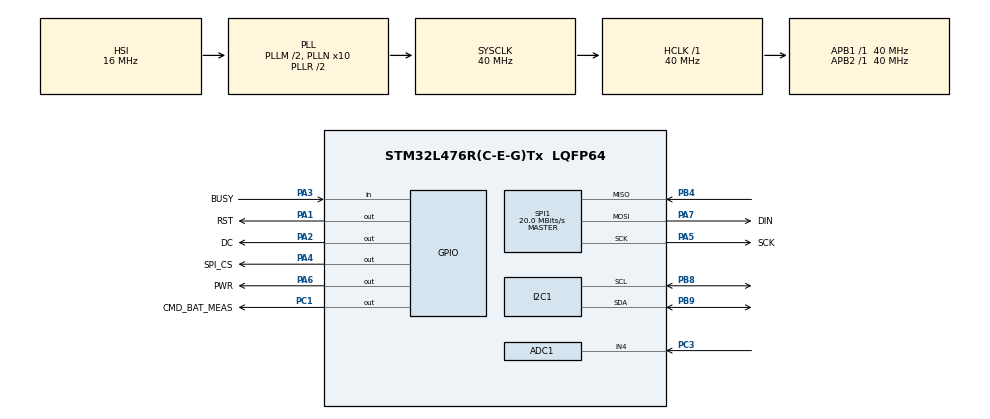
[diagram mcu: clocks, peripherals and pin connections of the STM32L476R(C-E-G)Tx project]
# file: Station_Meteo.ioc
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ADC1.Channel-2\#ChannelRegularConversion=ADC_CHANNEL_4
ADC1.ClockPrescaler=ADC_CLOCK_ASYNC_DIV6
ADC1.ContinuousConvMode=DISABLE
ADC1.NbrOfConversion=1
ADC1.NbrOfConversionFlag=1
ADC1.Offset-2\#ChannelRegularConversion=75
ADC1.OffsetNumber-2\#ChannelRegularConversion=ADC_OFFSET_NONE
ADC1.OversamplingMode=ENABLE
ADC1.Rank-2\#ChannelRegularConversion=1
ADC1.Ratio=ADC_OVERSAMPLING_RATIO_256
ADC1.Resolution=ADC_RESOLUTION_12B
ADC1.RightBitShift=ADC_RIGHTBITSHIFT_8
ADC1.SamplingTime-2\#ChannelRegularConversion=ADC_SAMPLETIME_640CYCLES_5
ADC1.master=1
I2C1.Timing=0x00D09BE3
Mcu.Family=STM32L4
Mcu.Name=STM32L476R(C-E-G)Tx
Mcu.Package=LQFP64
NVIC.PriorityGroup=NVIC_PRIORITYGROUP_4
NVIC.RTC_WKUP_IRQn=true\:0\:0\:false\:false\:true\:true\:true\:true
PA1.GPIO_Label=RST
PA1.PinState=GPIO_PIN_SET
PA1.Signal=GPIO_Output
PA13\ (JTMS-SWDIO).GPIO_Label=TMS
PA13\ (JTMS-SWDIO).Mode=Serial_Wire
PA13\ (JTMS-SWDIO).Signal=SYS_JTMS-SWDIO
PA14\ (JTCK-SWCLK).GPIO_Label=TCK
PA14\ (JTCK-SWCLK).Mode=Serial_Wire
PA14\ (JTCK-SWCLK).Signal=SYS_JTCK-SWCLK
PA2.GPIO_Label=DC
PA2.Signal=GPIO_Output
PA3.GPIO_Label=BUSY
PA3.Signal=GPIO_Input
PA4.GPIO_Label=SPI_CS
PA4.Signal=GPIO_Output
PA5.GPIO_Label=SCK
PA5.GPIO_Speed=GPIO_SPEED_FREQ_VERY_HIGH
PA5.Mode=Full_Duplex_Master
PA5.Signal=SPI1_SCK
PA6.GPIO_Label=PWR
PA6.Signal=GPIO_Output
PA7.GPIO_Label=DIN
PA7.GPIO_Speed=GPIO_SPEED_FREQ_VERY_HIGH
PA7.Mode=Full_Duplex_Master
PA7.Signal=SPI1_MOSI
PB4\ (NJTRST).GPIO_Speed=GPIO_SPEED_FREQ_VERY_HIGH
PB4\ (NJTRST).Mode=Full_Duplex_Master
PB4\ (NJTRST).Signal=SPI1_MISO
PB8.Mode=I2C
PB8.Signal=I2C1_SCL
PB9.Mode=I2C
PB9.Signal=I2C1_SDA
PC1.GPIO_Label=CMD_BAT_MEAS
PC1.Signal=GPIO_Output
PC14-OSC32_IN\ (PC14).Mode=LSE-External-Oscillator
PC14-OSC32_IN\ (PC14).Signal=RCC_OSC32_IN
PC15-OSC32_OUT\ (PC15).Mode=LSE-External-Oscillator
PC15-OSC32_OUT\ (PC15).Signal=RCC_OSC32_OUT
PC3.Signal=ADCx_IN4
PH0-OSC_IN\ (PH0).Signal=RCC_OSC_IN
PH1-OSC_OUT\ (PH1).Signal=RCC_OSC_OUT
ProjectManager.HeapSize=0x200
ProjectManager.StackSize=0x400
ProjectManager.TargetToolchain=STM32CubeIDE
RCC.ADCFreq_Value=32000000
RCC.AHBFreq_Value=40000000
RCC.APB1Freq_Value=40000000
RCC.APB1TimFreq_Value=40000000
RCC.APB2Freq_Value=40000000
RCC.APB2TimFreq_Value=40000000
RCC.CortexFreq_Value=40000000
RCC.HCLKFreq_Value=40000000
RCC.HSE_VALUE=8000000
RCC.HSI_VALUE=16000000
RCC.MSI_VALUE=4000000
RCC.PLLM=2
RCC.PLLN=10
RCC.PLLSourceVirtual=RCC_PLLSOURCE_HSI
RCC.PREFETCH_ENABLE=1
RCC.RTCClockSelection=RCC_RTCCLKSOURCE_LSE
RCC.SYSCLKFreq_VALUE=40000000
RCC.SYSCLKSource=RCC_SYSCLKSOURCE_PLLCLK
RCC.USBFreq_Value=32000000
RCC.VCOOutputFreq_Value=80000000
RTC.DayLightSaving=RTC_DAYLIGHTSAVING_SUB1H
RTC.WakeUpClock-WakeUp=RTC_WAKEUPCLOCK_CK_SPRE_16BITS
SH.ADCx_IN4.0=ADC1_IN4,IN4-Single-Ended
SPI1.BaudRatePrescaler=SPI_BAUDRATEPRESCALER_2
SPI1.CalculateBaudRate=20.0 MBits/s
SPI1.DataSize=SPI_DATASIZE_8BIT
SPI1.Direction=SPI_DIRECTION_2LINES
SPI1.Mode=SPI_MODE_MASTER
SPI1.NSSPMode=SPI_NSS_PULSE_ENABLE
SPI1.VirtualType=VM_MASTER
VP_RTC_VS_RTC_Activate.Mode=RTC_Enabled
VP_RTC_VS_RTC_Calendar.Mode=RTC_Calendar
VP_RTC_VS_RTC_WakeUp_intern.Mode=WakeUp
board=NUCLEO-L476RG

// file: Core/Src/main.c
/* USER CODE BEGIN Header */
/**
  ******************************************************************************
  * @file           : main.c
  * @brief          : Main program body
  ******************************************************************************
  * @attention
  *
  * Copyright (c) 2026 STMicroelectronics.
  * All rights reserved.
  *
  * This software is licensed under terms that can be found in the LICENSE file
  * in the root directory of this software component.
  * If no LICENSE file comes with this software, it is provided AS-IS.
  *
  ******************************************************************************
  */
/* USER CODE END Header */
#include "main.h"

/* USER CODE BEGIN Includes */
#include "Station_meteo.h"

/* USER CODE END Includes */

ADC_HandleTypeDef hadc1;

I2C_HandleTypeDef hi2c1;

RTC_HandleTypeDef hrtc;

SPI_HandleTypeDef hspi1;

void SystemClock_Config(void);
static void MX_GPIO_Init(void);
static void MX_RTC_Init(void);

/* USER CODE BEGIN 0 */
Station_meteo_t Station_meteo;

/* USER CODE END 0 */

int main(void)
{

  /* MCU Configuration--------------------------------------------------------*/

  /* Reset of all peripherals, Initializes the Flash interface and the Systick. */
  HAL_Init();

  /* Configure the system clock */
  SystemClock_Config();

  /* Initialize all configured peripherals */
  MX_GPIO_Init();
  MX_I2C1_Init();
  MX_SPI1_Init();
  MX_RTC_Init();
  MX_ADC1_Init();
  /* USER CODE BEGIN 2 */

  Station_meteo_init(&Station_meteo);
  /* USER CODE END 2 */

  /* Infinite loop */
  while (1)
  {

    /* USER CODE BEGIN 3 */
 	  Station_meteo_process(&Station_meteo);

  }
  /* USER CODE END 3 */
}

void SystemClock_Config(void)
{
  RCC_OscInitTypeDef RCC_OscInitStruct = {0};
  RCC_ClkInitTypeDef RCC_ClkInitStruct = {0};

  /** Configure the main internal regulator output voltage
  */
  if (HAL_PWREx_ControlVoltageScaling(PWR_REGULATOR_VOLTAGE_SCALE1) != HAL_OK)
  {
    Error_Handler();
  }

  /** Configure LSE Drive Capability
  */
  HAL_PWR_EnableBkUpAccess();
  __HAL_RCC_LSEDRIVE_CONFIG(RCC_LSEDRIVE_LOW);

  /** Initializes the RCC Oscillators according to the specified parameters
  * in the RCC_OscInitTypeDef structure.
  */
  RCC_OscInitStruct.OscillatorType = RCC_OSCILLATORTYPE_HSI|RCC_OSCILLATORTYPE_LSE;
  RCC_OscInitStruct.LSEState = RCC_LSE_ON;
  RCC_OscInitStruct.HSIState = RCC_HSI_ON;
  RCC_OscInitStruct.HSICalibrationValue = RCC_HSICALIBRATION_DEFAULT;
  RCC_OscInitStruct.PLL.PLLState = RCC_PLL_ON;
  RCC_OscInitStruct.PLL.PLLSource = RCC_PLLSOURCE_HSI;
  RCC_OscInitStruct.PLL.PLLM = 2;
  RCC_OscInitStruct.PLL.PLLN = 10;
  RCC_OscInitStruct.PLL.PLLP = RCC_PLLP_DIV7;
  RCC_OscInitStruct.PLL.PLLQ = RCC_PLLQ_DIV2;
  RCC_OscInitStruct.PLL.PLLR = RCC_PLLR_DIV2;
  if (HAL_RCC_OscConfig(&RCC_OscInitStruct) != HAL_OK)
  {
    Error_Handler();
  }

  /** Initializes the CPU, AHB and APB buses clocks
  */
  RCC_ClkInitStruct.ClockType = RCC_CLOCKTYPE_HCLK|RCC_CLOCKTYPE_SYSCLK
                              |RCC_CLOCKTYPE_PCLK1|RCC_CLOCKTYPE_PCLK2;
  RCC_ClkInitStruct.SYSCLKSource = RCC_SYSCLKSOURCE_PLLCLK;
  RCC_ClkInitStruct.AHBCLKDivider = RCC_SYSCLK_DIV1;
  RCC_ClkInitStruct.APB1CLKDivider = RCC_HCLK_DIV1;
  RCC_ClkInitStruct.APB2CLKDivider = RCC_HCLK_DIV1;

  if (HAL_RCC_ClockConfig(&RCC_ClkInitStruct, FLASH_LATENCY_2) != HAL_OK)
  {
    Error_Handler();
  }
}

void MX_ADC1_Init(void)
{

  ADC_MultiModeTypeDef multimode = {0};
  ADC_ChannelConfTypeDef sConfig = {0};

  /** Common config
  */
  hadc1.Instance = ADC1;
  hadc1.Init.ClockPrescaler = ADC_CLOCK_ASYNC_DIV6;
  hadc1.Init.Resolution = ADC_RESOLUTION_12B;
  hadc1.Init.DataAlign = ADC_DATAALIGN_RIGHT;
  hadc1.Init.ScanConvMode = ADC_SCAN_DISABLE;
  hadc1.Init.EOCSelection = ADC_EOC_SINGLE_CONV;
  hadc1.Init.LowPowerAutoWait = DISABLE;
  hadc1.Init.ContinuousConvMode = DISABLE;
  hadc1.Init.NbrOfConversion = 1;
  hadc1.Init.DiscontinuousConvMode = DISABLE;
  hadc1.Init.ExternalTrigConv = ADC_SOFTWARE_START;
  hadc1.Init.ExternalTrigConvEdge = ADC_EXTERNALTRIGCONVEDGE_NONE;
  hadc1.Init.DMAContinuousRequests = DISABLE;
  hadc1.Init.Overrun = ADC_OVR_DATA_PRESERVED;
  hadc1.Init.OversamplingMode = ENABLE;
  hadc1.Init.Oversampling.Ratio = ADC_OVERSAMPLING_RATIO_256;
  hadc1.Init.Oversampling.RightBitShift = ADC_RIGHTBITSHIFT_8;
  hadc1.Init.Oversampling.TriggeredMode = ADC_TRIGGEREDMODE_SINGLE_TRIGGER;
  hadc1.Init.Oversampling.OversamplingStopReset = ADC_REGOVERSAMPLING_CONTINUED_MODE;
  if (HAL_ADC_Init(&hadc1) != HAL_OK)
  {
    Error_Handler();
  }

  /** Configure the ADC multi-mode
  */
  multimode.Mode = ADC_MODE_INDEPENDENT;
  if (HAL_ADCEx_MultiModeConfigChannel(&hadc1, &multimode) != HAL_OK)
  {
    Error_Handler();
  }

  /** Configure Regular Channel
  */
  sConfig.Channel = ADC_CHANNEL_4;
  sConfig.Rank = ADC_REGULAR_RANK_1;
  sConfig.SamplingTime = ADC_SAMPLETIME_640CYCLES_5;
  sConfig.SingleDiff = ADC_SINGLE_ENDED;
  sConfig.OffsetNumber = ADC_OFFSET_NONE;
  sConfig.Offset = 75;
  if (HAL_ADC_ConfigChannel(&hadc1, &sConfig) != HAL_OK)
  {
    Error_Handler();
  }

}

void MX_I2C1_Init(void)
{

  hi2c1.Instance = I2C1;
  hi2c1.Init.Timing = 0x00D09BE3;
  hi2c1.Init.OwnAddress1 = 0;
  hi2c1.Init.AddressingMode = I2C_ADDRESSINGMODE_7BIT;
  hi2c1.Init.DualAddressMode = I2C_DUALADDRESS_DISABLE;
  hi2c1.Init.OwnAddress2 = 0;
  hi2c1.Init.OwnAddress2Masks = I2C_OA2_NOMASK;
  hi2c1.Init.GeneralCallMode = I2C_GENERALCALL_DISABLE;
  hi2c1.Init.NoStretchMode = I2C_NOSTRETCH_DISABLE;
  if (HAL_I2C_Init(&hi2c1) != HAL_OK)
  {
    Error_Handler();
  }

  /** Configure Analogue filter
  */
  if (HAL_I2CEx_ConfigAnalogFilter(&hi2c1, I2C_ANALOGFILTER_ENABLE) != HAL_OK)
  {
    Error_Handler();
  }

  /** Configure Digital filter
  */
  if (HAL_I2CEx_ConfigDigitalFilter(&hi2c1, 0) != HAL_OK)
  {
    Error_Handler();
  }

}

static void MX_RTC_Init(void)
{

  RTC_TimeTypeDef sTime = {0};
  RTC_DateTypeDef sDate = {0};

  /** Initialize RTC Only
  */
  hrtc.Instance = RTC;
  hrtc.Init.HourFormat = RTC_HOURFORMAT_24;
  hrtc.Init.AsynchPrediv = 127;
  hrtc.Init.SynchPrediv = 255;
  hrtc.Init.OutPut = RTC_OUTPUT_DISABLE;
  hrtc.Init.OutPutRemap = RTC_OUTPUT_REMAP_NONE;
  hrtc.Init.OutPutPolarity = RTC_OUTPUT_POLARITY_HIGH;
  hrtc.Init.OutPutType = RTC_OUTPUT_TYPE_OPENDRAIN;
  if (HAL_RTC_Init(&hrtc) != HAL_OK)
  {
    Error_Handler();
  }

  /** Initialize RTC and set the Time and Date
  */
  sTime.Hours = 0x0;
  sTime.Minutes = 0x0;
  sTime.Seconds = 0x0;
  sTime.DayLightSaving = RTC_DAYLIGHTSAVING_SUB1H;
  sTime.StoreOperation = RTC_STOREOPERATION_RESET;
  if (HAL_RTC_SetTime(&hrtc, &sTime, RTC_FORMAT_BCD) != HAL_OK)
  {
    Error_Handler();
  }
  sDate.WeekDay = RTC_WEEKDAY_MONDAY;
  sDate.Month = RTC_MONTH_JANUARY;
  sDate.Date = 0x1;
  sDate.Year = 0x0;

  if (HAL_RTC_SetDate(&hrtc, &sDate, RTC_FORMAT_BCD) != HAL_OK)
  {
    Error_Handler();
  }

}

void MX_SPI1_Init(void)
{

  /* SPI1 parameter configuration*/
  hspi1.Instance = SPI1;
  hspi1.Init.Mode = SPI_MODE_MASTER;
  hspi1.Init.Direction = SPI_DIRECTION_2LINES;
  hspi1.Init.DataSize = SPI_DATASIZE_8BIT;
  hspi1.Init.CLKPolarity = SPI_POLARITY_LOW;
  hspi1.Init.CLKPhase = SPI_PHASE_1EDGE;
  hspi1.Init.NSS = SPI_NSS_SOFT;
  hspi1.Init.BaudRatePrescaler = SPI_BAUDRATEPRESCALER_2;
  hspi1.Init.FirstBit = SPI_FIRSTBIT_MSB;
  hspi1.Init.TIMode = SPI_TIMODE_DISABLE;
  hspi1.Init.CRCCalculation = SPI_CRCCALCULATION_DISABLE;
  hspi1.Init.CRCPolynomial = 7;
  hspi1.Init.CRCLength = SPI_CRC_LENGTH_DATASIZE;
  hspi1.Init.NSSPMode = SPI_NSS_PULSE_ENABLE;
  if (HAL_SPI_Init(&hspi1) != HAL_OK)
  {
    Error_Handler();
  }

}

static void MX_GPIO_Init(void)
{
  GPIO_InitTypeDef GPIO_InitStruct = {0};

  /* GPIO Ports Clock Enable */
  __HAL_RCC_GPIOC_CLK_ENABLE();
  __HAL_RCC_GPIOH_CLK_ENABLE();
  __HAL_RCC_GPIOA_CLK_ENABLE();
  __HAL_RCC_GPIOB_CLK_ENABLE();
  __HAL_RCC_GPIOD_CLK_ENABLE();

  /*Configure GPIO pin Output Level */
  HAL_GPIO_WritePin(CMD_BAT_MEAS_GPIO_Port, CMD_BAT_MEAS_Pin, GPIO_PIN_RESET);

  /*Configure GPIO pin Output Level */
  HAL_GPIO_WritePin(RST_GPIO_Port, RST_Pin, GPIO_PIN_SET);

  /*Configure GPIO pin Output Level */
  HAL_GPIO_WritePin(GPIOA, DC_Pin|SPI_CS_Pin|PWR_Pin, GPIO_PIN_RESET);

  /*Configure GPIO pins : PC13 PC0 PC2 PC4
                           PC5 PC6 PC7 PC8
                           PC9 PC10 PC11 PC12 */
  GPIO_InitStruct.Pin = GPIO_PIN_13|GPIO_PIN_0|GPIO_PIN_2|GPIO_PIN_4
                          |GPIO_PIN_5|GPIO_PIN_6|GPIO_PIN_7|GPIO_PIN_8
                          |GPIO_PIN_9|GPIO_PIN_10|GPIO_PIN_11|GPIO_PIN_12;
  GPIO_InitStruct.Mode = GPIO_MODE_ANALOG;
  GPIO_InitStruct.Pull = GPIO_NOPULL;
  HAL_GPIO_Init(GPIOC, &GPIO_InitStruct);

  /*Configure GPIO pin : CMD_BAT_MEAS_Pin */
  GPIO_InitStruct.Pin = CMD_BAT_MEAS_Pin;
  GPIO_InitStruct.Mode = GPIO_MODE_OUTPUT_PP;
  GPIO_InitStruct.Pull = GPIO_NOPULL;
  GPIO_InitStruct.Speed = GPIO_SPEED_FREQ_LOW;
  HAL_GPIO_Init(CMD_BAT_MEAS_GPIO_Port, &GPIO_InitStruct);

  /*Configure GPIO pins : PA0 PA8 PA9 PA10
                           PA11 PA12 PA15 */
  GPIO_InitStruct.Pin = GPIO_PIN_0|GPIO_PIN_8|GPIO_PIN_9|GPIO_PIN_10
                          |GPIO_PIN_11|GPIO_PIN_12|GPIO_PIN_15;
  GPIO_InitStruct.Mode = GPIO_MODE_ANALOG;
  GPIO_InitStruct.Pull = GPIO_NOPULL;
  HAL_GPIO_Init(GPIOA, &GPIO_InitStruct);

  /*Configure GPIO pins : RST_Pin DC_Pin SPI_CS_Pin PWR_Pin */
  GPIO_InitStruct.Pin = RST_Pin|DC_Pin|SPI_CS_Pin|PWR_Pin;
  GPIO_InitStruct.Mode = GPIO_MODE_OUTPUT_PP;
  GPIO_InitStruct.Pull = GPIO_NOPULL;
  GPIO_InitStruct.Speed = GPIO_SPEED_FREQ_LOW;
  HAL_GPIO_Init(GPIOA, &GPIO_InitStruct);

  /*Configure GPIO pin : BUSY_Pin */
  GPIO_InitStruct.Pin = BUSY_Pin;
  GPIO_InitStruct.Mode = GPIO_MODE_INPUT;
  GPIO_InitStruct.Pull = GPIO_NOPULL;
  HAL_GPIO_Init(BUSY_GPIO_Port, &GPIO_InitStruct);

  /*Configure GPIO pins : PB0 PB1 PB2 PB10
                           PB11 PB12 PB13 PB14
                           PB15 PB3 PB5 PB6
                           PB7 */
  GPIO_InitStruct.Pin = GPIO_PIN_0|GPIO_PIN_1|GPIO_PIN_2|GPIO_PIN_10
                          |GPIO_PIN_11|GPIO_PIN_12|GPIO_PIN_13|GPIO_PIN_14
                          |GPIO_PIN_15|GPIO_PIN_3|GPIO_PIN_5|GPIO_PIN_6
                          |GPIO_PIN_7;
  GPIO_InitStruct.Mode = GPIO_MODE_ANALOG;
  GPIO_InitStruct.Pull = GPIO_NOPULL;
  HAL_GPIO_Init(GPIOB, &GPIO_InitStruct);

  /*Configure GPIO pin : PD2 */
  GPIO_InitStruct.Pin = GPIO_PIN_2;
  GPIO_InitStruct.Mode = GPIO_MODE_ANALOG;
  GPIO_InitStruct.Pull = GPIO_NOPULL;
  HAL_GPIO_Init(GPIOD, &GPIO_InitStruct);

}

void Error_Handler(void)
{
  __disable_irq();
  while (1)
  {
  }
}
